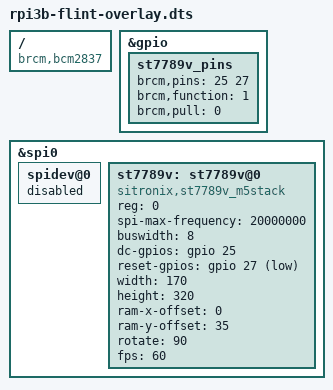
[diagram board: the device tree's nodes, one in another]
// SPDX-License-Identifier: GPL-2.0
// Device Tree overlay for flint on Raspberry Pi 3B+
//
// Differences from cardputerzero-overlay:
//   - No M5IOE1 / PY32 IO expander (backlight always on, wired to 3V3)
//   - Display RST on GPIO27 (direct GPIO, not via M5IOE1 PYG5)
//   - No audio (ES8389 not present)
//   - No TCA8418 keyboard (USB HID keyboard used instead)
//   - compatible = "brcm,bcm2837" (RPi 3B+ SoC)

/dts-v1/;
/plugin/;

/ {
    compatible = "brcm,bcm2837";

    // fragment@0 — GPIO pin assignments
    fragment@0 {
        target = <&gpio>;
        __overlay__ {
            st7789v_pins: st7789v_pins {
                // GPIO25 = DC (Data/Command), GPIO27 = RST (active-low)
                brcm,pins = <25 27>;
                brcm,function = <1>;    // output
                brcm,pull = <0>;        // no pull
            };
        };
    };

    // fragment@1 — SPI0: ST7789V display on CS0, disable default spidev
    fragment@1 {
        target = <&spi0>;
        __overlay__ {
            #address-cells = <1>;
            #size-cells = <0>;
            status = "okay";

            spidev@0 {
                status = "disabled";
            };

            st7789v: st7789v@0 {
                compatible = "sitronix,st7789v_m5stack";
                reg = <0>;                      // CS0 = GPIO8
                // 50MHz is fine on the real CardputerZero's short PCB traces;
                // over breadboard/jumper-wire runs it causes visible SPI
                // signal corruption (garbled/noisy regions on screen).
                spi-max-frequency = <20000000>;
                buswidth = <8>;                 // required by the fbtft-based driver;
                                                 // missing this fails probe with -EINVAL
                dc-gpios = <&gpio 25 0>;        // DC = GPIO25, active-high
                reset-gpios = <&gpio 27 1>;     // RST = GPIO27, active-low
                width = <170>;
                height = <320>;
                // Property names MUST match what fb_st7789v_m5stack actually reads
                // (github.com/m5stack/m5stack-linux-dtoverlays, modules/st7789v-1.0):
                //   * fbtft core reads "rotate", NOT "rotation". With the wrong name
                //     var.rotate stays 0, set_var() takes case 0 (no MADCTL_MV/MX/MY),
                //     and the panel is stuck in portrait — hence "rotation is wrong".
                //   * for compatible "sitronix,st7789v_m5stack" the active addr-window
                //     function is fbtft_set_addr_win(), which adds the DT props
                //     "ram-x-offset"/"ram-y-offset". It does NOT use "x-offset"/
                //     "y-offset", nor set_var()'s x_offset/y_offset globals (those are
                //     dead code for this compatible — only the "minipitft13" variant's
                //     set_addr_win consumes them). Without ram-*-offset the 170-wide
                //     window is addressed from column 0 of the panel's 240-wide GRAM,
                //     leaving an unwritten band that shows as RGB noise on one edge.
                // Names/rotate match the vendor's own reference overlay for this
                // exact 170x320 panel (st7789v_m5stack.dts: rotate=90). The vendor
                // uses ram-y-offset=32, but this board's panel unit needed 35
                // ((240-170)/2, the datasheet-centered value): at 32 the top 2px
                // border was clipped off-screen and a ~3px unwritten noise band
                // showed at the bottom. Verified on real RPi 3B+ hardware.
                ram-x-offset = <0>;
                ram-y-offset = <35>;
                rotate = <90>;
                fps = <60>;
            };
        };
    };
};
